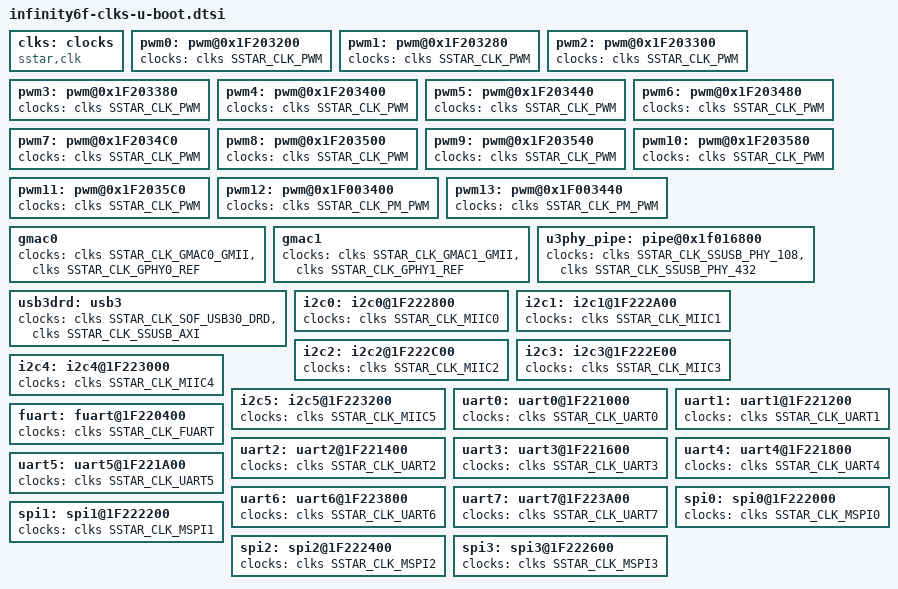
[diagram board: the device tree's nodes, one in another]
/*
* infinity6f-clks-u-boot.dtsi- Sigmastar
*
* Copyright (c) [2019~2020] SigmaStar Technology.
*
*
* This software is licensed under the terms of the GNU General Public
* License version 2, as published by the Free Software Foundation, and
* may be copied, distributed, and modified under those terms.
*
* This program is distributed in the hope that it will be useful,
* but WITHOUT ANY WARRANTY; without even the implied warranty of
* MERCHANTABILITY or FITNESS FOR A PARTICULAR PURPOSE.  See the
* GNU General Public License version 2 for more details.
*
*/
#include "../../../drivers/sstar/clk/infinity6f/hal_clk.h"

clks: clocks{
    compatible = "sstar,clk";
    #clock-cells = <1>;
};

pwm0: pwm@0x1F203200 {
    clocks = <&clks SSTAR_CLK_PWM>;
};

pwm1: pwm@0x1F203280 {
    clocks = <&clks SSTAR_CLK_PWM>;
};

pwm2: pwm@0x1F203300 {
    clocks = <&clks SSTAR_CLK_PWM>;
};

pwm3: pwm@0x1F203380 {
    clocks = <&clks SSTAR_CLK_PWM>;
};

pwm4: pwm@0x1F203400 {
    clocks = <&clks SSTAR_CLK_PWM>;
};

pwm5: pwm@0x1F203440 {
    clocks = <&clks SSTAR_CLK_PWM>;
};

pwm6: pwm@0x1F203480 {
    clocks = <&clks SSTAR_CLK_PWM>;
};

pwm7: pwm@0x1F2034C0 {
    clocks = <&clks SSTAR_CLK_PWM>;
};

pwm8: pwm@0x1F203500 {
    clocks = <&clks SSTAR_CLK_PWM>;
};

pwm9: pwm@0x1F203540 {
    clocks = <&clks SSTAR_CLK_PWM>;
};

pwm10: pwm@0x1F203580 {
    clocks = <&clks SSTAR_CLK_PWM>;
};

pwm11: pwm@0x1F2035C0 {
    clocks = <&clks SSTAR_CLK_PWM>;
};

pwm12: pwm@0x1F003400 {
    clocks = <&clks SSTAR_CLK_PM_PWM>;
};

pwm13: pwm@0x1F003440 {
    clocks = <&clks SSTAR_CLK_PM_PWM>;
};

gmac0: gmac0 {
    clocks = <&clks SSTAR_CLK_GMAC0_GMII>, <&clks SSTAR_CLK_GPHY0_REF>;
};

gmac1: gmac1{
    clocks = <&clks SSTAR_CLK_GMAC1_GMII>, <&clks SSTAR_CLK_GPHY1_REF>;
};

u3phy_pipe: pipe@0x1f016800 {
    clocks = <&clks SSTAR_CLK_SSUSB_PHY_108>, <&clks SSTAR_CLK_SSUSB_PHY_432>;
};

usb3drd: usb3 {
    clocks = <&clks SSTAR_CLK_SOF_USB30_DRD>, <&clks SSTAR_CLK_SSUSB_AXI>;
};

i2c0: i2c0@1F222800 {
    clocks = <&clks SSTAR_CLK_MIIC0>;
};

i2c1: i2c1@1F222A00 {
    clocks = <&clks SSTAR_CLK_MIIC1>;
};

i2c2: i2c2@1F222C00 {
    clocks = <&clks SSTAR_CLK_MIIC2>;
};

i2c3: i2c3@1F222E00 {
    clocks = <&clks SSTAR_CLK_MIIC3>;
};

i2c4: i2c4@1F223000 {
    clocks = <&clks SSTAR_CLK_MIIC4>;
};

i2c5: i2c5@1F223200 {
    clocks = <&clks SSTAR_CLK_MIIC5>;
};

uart0: uart0@1F221000 {
    clocks = <&clks SSTAR_CLK_UART0>;
};

uart1: uart1@1F221200 {
    clocks = <&clks SSTAR_CLK_UART1>;
};

fuart: fuart@1F220400 {
    clocks = <&clks SSTAR_CLK_FUART>;
};

uart2: uart2@1F221400 {
    clocks = <&clks SSTAR_CLK_UART2>;
};

uart3: uart3@1F221600 {
    clocks = <&clks SSTAR_CLK_UART3>;
};

uart4: uart4@1F221800 {
    clocks = <&clks SSTAR_CLK_UART4>;
};

uart5: uart5@1F221A00 {
    clocks = <&clks SSTAR_CLK_UART5>;
};

uart6: uart6@1F223800 {
    clocks = <&clks SSTAR_CLK_UART6>;
};

uart7: uart7@1F223A00 {
    clocks = <&clks SSTAR_CLK_UART7>;
};

spi0: spi0@1F222000 {
    clocks = <&clks SSTAR_CLK_MSPI0>;
};

spi1: spi1@1F222200 {
    clocks = <&clks SSTAR_CLK_MSPI1>;
};

spi2: spi2@1F222400 {
    clocks = <&clks SSTAR_CLK_MSPI2>;
};

spi3: spi3@1F222600 {
    clocks = <&clks SSTAR_CLK_MSPI3>;
};

